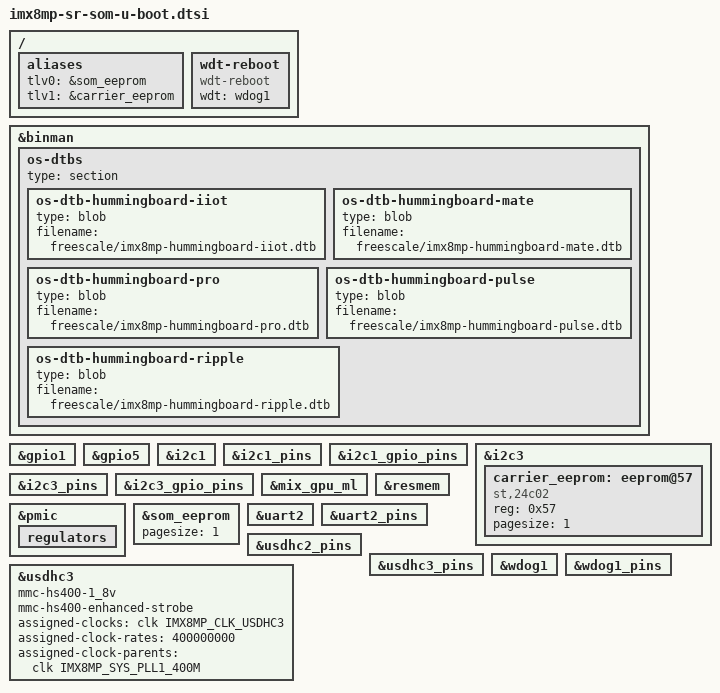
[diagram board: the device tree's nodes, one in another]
// SPDX-License-Identifier: (GPL-2.0+ OR MIT)
/*
 * Copyright 2025 Josua Mayer <josua@solid-run.com>
 */
#include "imx8mp-sec-def.h"

#include "imx8mp-u-boot.dtsi"

/ {
	aliases {
		tlv0 = &som_eeprom;
		tlv1 = &carrier_eeprom;
	};

	wdt-reboot {
		compatible = "wdt-reboot";
		wdt = <&wdog1>;
		bootph-all;
	};
};

&binman {
	os-dtbs {
		type = "section";

		os-dtb-hummingboard-iiot {
			type = "blob";
			filename = "freescale/imx8mp-hummingboard-iiot.dtb";
		};

		os-dtb-hummingboard-mate {
			type = "blob";
			filename = "freescale/imx8mp-hummingboard-mate.dtb";
		};

		os-dtb-hummingboard-pro {
			type = "blob";
			filename = "freescale/imx8mp-hummingboard-pro.dtb";
		};

		os-dtb-hummingboard-pulse {
			type = "blob";
			filename = "freescale/imx8mp-hummingboard-pulse.dtb";
		};

		os-dtb-hummingboard-ripple {
			type = "blob";
			filename = "freescale/imx8mp-hummingboard-ripple.dtb";
		};
	};
};

&gpio1 {
	bootph-all;
};

&gpio5 {
	bootph-all;
};

&i2c1 {
	bootph-all;
};

&i2c1_pins {
	bootph-all;
};

&i2c1_gpio_pins {
	bootph-all;
};

&i2c3 {
	bootph-all;

	/* enable known eeprom for board identification */
	carrier_eeprom: eeprom@57 {
		compatible = "st,24c02", "atmel,24c02";
		reg = <0x57>;
		pagesize = <1>;
		bootph-pre-ram;
	};
};

&i2c3_pins {
	bootph-all;
};

&i2c3_gpio_pins {
	bootph-all;
};

&mix_gpu_ml {
	/* drop reference to legacy memory reservation */
	/delete-property/ memory-region;
};

&pmic {
	bootph-all;

	regulators {
		bootph-all;
	};
};

/* Drop legacy memory reservation above 4GB.
 * SolidRun SoMs start at 1Gb SDRAM, hence this area was always invalid.
 */
&resmem {
	/delete-node/ gpu_reserved@100000000;
};

&som_eeprom {
	pagesize = <1>;
	bootph-all;
};

&uart2 {
	bootph-all;
};

&uart2_pins {
	bootph-all;
};

&usdhc2_pins {
	bootph-all;
};

&usdhc3_pins {
	bootph-all;
};

&usdhc3 {
	bootph-all;
	mmc-hs400-1_8v;
	mmc-hs400-enhanced-strobe;
	assigned-clocks = <&clk IMX8MP_CLK_USDHC3>;
	assigned-clock-rates = <400000000>;
	assigned-clock-parents = <&clk IMX8MP_SYS_PLL1_400M>;
};

&wdog1 {
	bootph-all;
};

&wdog1_pins {
	bootph-all;
};
